# psoc4100sp register map
Vendor: Infineon Technologies; Series: PSOC4100Sp; File version: 1.0
CPU: CM0PLUS r0p1, little endian, MPU, no FPU, VTOR, 2 interrupt priority bits, 28 interrupts
Registers are 32-bit, read-write, reset 0x0 unless marked. A register's access mark holds for its fields unless they carry their own. Offsets are from the block's base; [hi:lo] are bit positions; lines under a group give offsets from that group; {n}, {i} and the like mark numbered series; <NAME> marks a mode.

## CAN — CAN Controller
Base 0x402E0000
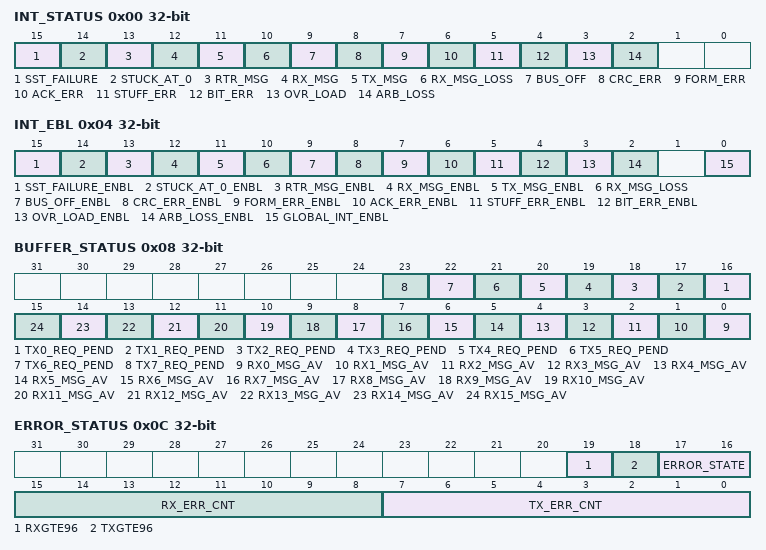
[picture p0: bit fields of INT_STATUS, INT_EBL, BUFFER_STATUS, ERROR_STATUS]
0x00 INT_STATUS — Interrupt Status
  [15] SST_FAILURE write-1-clears — Single shot transmission failure 0: Normal operation 1: A buffer set for single shot transmission experienced an arbitration loss or a bus error during transmission The sst_failure interrupt is set as well when the CAN controller is being stopped while an SST message is in the transmit buffer. user should transmit or remove respective SST messages before stopping the IP, to avoid triggering SST_FAILURE after writing COMMAND.RUN=0.
  [14] STUCK_AT_0 write-1-clears — Stuck at dominant error 0: Normal Operation 1: Indicates if the rx input remains stuack at 0 (dominant level) for more than 16 consecutive bit times. The 'stuck at 0' condition is checked, only when COMMAND.RUN is set
  [13] RTR_MSG write-1-clears — RTR auto-reply message sent 0: Normal operation 1: Indicates that a RTR auto-reply message was sent
  [12] RX_MSG write-1-clears — Indicates that a message was received 0: Normal operation 1: A new message was successfully received and stored in a receive buffer which has its RxIntEBL flag asserted.
  [11] TX_MSG write-1-clears — Indicates that a message was sent 0: Normal operation 1: A message was successfully sent from a transmit buffer which has its TxIntEbl flag asserted.
  [10] RX_MSG_LOSS write-1-clears — when a new message arrives, but the RxMessage flag MSG_AV is set and LINK_FLAG is not set, RX_MSG_LOSS is set, and the new message is discarded.
  [9] BUS_OFF write-1-clears — The CAN has reached the bus off state
  [8] CRC_ERR write-1-clears — A CAN CRC error was detected
  [7] FORM_ERR write-1-clears — A CAN message format error was detected please ignore this interrupt, when ERROR_STATUS.ERROR_STATE=2'B1x
  [6] ACK_ERR write-1-clears — An CAN message acknowledge error was detected
  [5] STUFF_ERR write-1-clears — A bit stuffing error was detected
  [4] BIT_ERR write-1-clears — A bit error was detected
  [3] OVR_LOAD write-1-clears — An overload frame was received, or reactive overload frame condition is detected (ISO-11898-1 section 10.11)
  [2] ARB_LOSS write-1-clears — The arbitration was lost while sending a message
0x04 INT_EBL — Interrupt Enable
  [15] SST_FAILURE_ENBL — See description in INT_STATUS
  [14] STUCK_AT_0_ENBL — See description in INT_STATUS
  [13] RTR_MSG_ENBL — See description in INT_STATUS
  [12] RX_MSG_ENBL — See description in INT_STATUS
  [11] TX_MSG_ENBL — See description in INT_STATUS
  [10] RX_MSG_LOSS — See description in INT_STATUS
  [9] BUS_OFF_ENBL — See description in INT_STATUS
  [8] CRC_ERR_ENBL — See description in INT_STATUS
  [7] FORM_ERR_ENBL — See description in INT_STATUS
  [6] ACK_ERR_ENBL — See description in INT_STATUS
  [5] STUFF_ERR_ENBL — See description in INT_STATUS
  [4] BIT_ERR_ENBL — See description in INT_STATUS
  [3] OVR_LOAD_ENBL — See description in INT_STATUS
  [2] ARB_LOSS_ENBL — See description in INT_STATUS
  [0] GLOBAL_INT_ENBL — global interrupt enable flag '0': All interrupts are disabled '1': Enabled interrupt sources are available
0x08 BUFFER_STATUS ro — RxMessage and TxMessage Buffer Status
  [n+16] TX{n}_REQ_PEND (n=0..7) — TxMessage Buffer Status
  [n] RX{n}_MSG_AV (n=0..15) — RxMessage Buffer Status
0x0C ERROR_STATUS ro — CAN Error Status
  [19] RXGTE96 — The Rx error counter is greater or equal 96
  [18] TXGTE96 — The Tx error counter is greater or equal 96
  [17:16] ERROR_STATE — The error state of the CAN node: '00': error active (normal operation) '01': error passive '1x': bus off
  [15:8] RX_ERR_CNT — The receive error counter according to the CAN 2.0 specification. When in bus-off state, this counter is used to count 128 groups of 11 recessive bits. it is fixed at 255
  [7:0] TX_ERR_CNT — The transmitter error counter according to the CAN standard. When it is greater than 255, it is fixed at 255
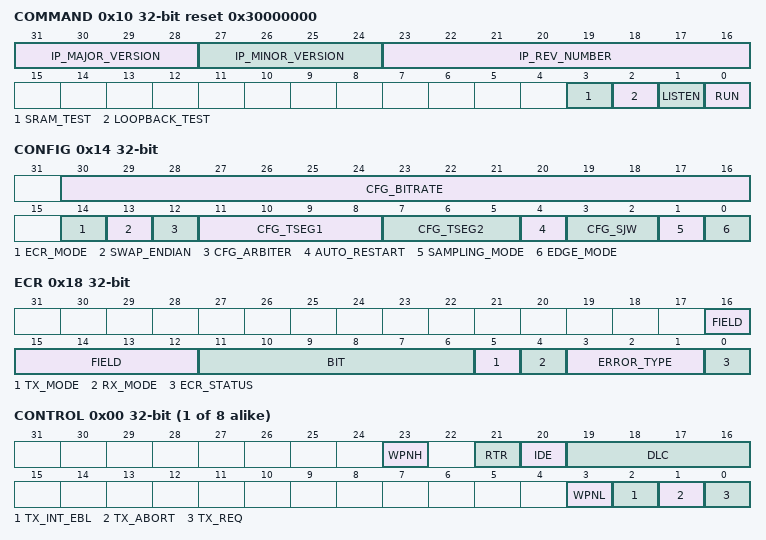
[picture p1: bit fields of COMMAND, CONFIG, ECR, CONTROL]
0x10 COMMAND reset 0x30000000 — CAN Command Register
  [31:28] IP_MAJOR_VERSION ro — IP Major Version Number
  [27:24] IP_MINOR_VERSION ro — IP Minor Version Number
  [23:16] IP_REV_NUMBER ro — IP Revision Number
  [3] SRAM_TEST — SRAM test mode '0': Normal operation '1': Enable SRAM test mode it can be set, only when the IP is stopped (COMMAND.RUN=0, and really finished transition from run mode), this mode will not be used, so it should never be set.
  [2] LOOPBACK_TEST — TEST_MODE[2]. With TEST_MODE[2:1], 00: normal operation 01: Listen-only mode, The output is held at 'R' level. The CANmodule-III is only listening. 10: external loopback mode 11: internal loopback mode
  [1] LISTEN — TEST_MODE[1]
  [0] RUN — Run/Stop mode: '0': Sets the CAN controller into stop mode. Stop mode can be granted only in 'bus idle' field Returns '0' when stopped. '1': Sets the CAN controller into run mode. Returns '1' when running.
0x14 CONFIG — CAN Configuration
  [30:16] CFG_BITRATE — Prescaler for generating the time quantum which defines the TQ: 0: One time quantum equals 1 clock cycle 1: One time quantum equals 2 clock cycles ... 32767: One time quantum equals 32768 clock cycles
  [14] ECR_MODE — Error Capture mode 0: Free running: The ECR register shows the current bit position within the CAN frame 1: Capture mode: The ecr register shows the bit position and type of the last captured CAN error.
  [13] SWAP_ENDIAN — Swap Endian - the byte position of the CAN receive and transmit data fields can be modified to match the endian setting of the processor or the used CAN protocol 0: CAN data byte position is not swapped (big endian) 1: CAN data byte position is swapped (little endian)
  [12] CFG_ARBITER — Transmit buffer arbiter '0': Round robin arbitration '1': Fixed priority arbitration
  [11:8] CFG_TSEG1 — Time segment 1 Length of the first time segment: tseg1 = cfg_tseg1 + 1 Time segment 1 includes the propagation time. cfg_tseg1=0 and cfg_tseg1=1 are not allowed.
  [7:5] CFG_TSEG2 — Time segment 2 Length of the second time segment: tseg2 = cfg_tseg2 + 1 cfg_tseg2=0 is not allowed; cfg_tseg2=1 is only allowed in direct sampling mode.
  [4] AUTO_RESTART — '0': After bus-off, the CAN core must be restarted by setting COMMAND.RUN register. This is the recommended setting. '1': After bus-off, the CAN core is restarting automatically after 128 groups of 11 recessive bits
  [3:2] CFG_SJW — Synchronization jump width - 1 sjw <= tseg1 and sjw <= tseg2
  [1] SAMPLING_MODE — CAN bus bit sampling '0': One sampling point is used in the receiver path '1': 3 sampling points with majority decision are used
  [0] EDGE_MODE — CAN bus synchronization logic '0': Edge from 'R' to 'D' is used for synchronization '1': Both edges are used Note, only 'R' to 'D' edge shall be used for synchronization per ISO-11898-1 spec, so this bit should always be set 0 (by default)
0x18 ECR — Error Capture Register
  [16:12] FIELD ro — Field - 0x00 : Stopped 0x01 : Synchronize 0x05 : Interframe 0x06 : Bus Idle 0x07 : Start of Frame 0x08 : Arbitration 0x09 : Control 0x0A : Data 0x0B : CRC 0x0C : ACK 0x0D : End of frame 0x10 : Error flag 0x11 : Error echo 0x12 : Error delimiter 0x18 : Overload flag 0x19 : Overload echo 0x1A : Overload delimiter Others : N/A
  [11:6] BIT ro — Bit number inside of Field
  [5] TX_MODE ro — TX Mode - 0: No status 1: CAN Controller is transmitter
  [4] RX_MODE ro — RX Mode - 0: No status 1: CAN Controller is receiver
  [3:1] ERROR_TYPE ro — Error type - 000 : Arbitration loss 001 : Bit Error 010 : Bit Stuffing Error 011 : Acknowledge Error 100 : Form Error 101 : CRC Error Others : N/A
  [0] ECR_STATUS — ECR STATUS - 0: ECR register captured an error, or it is in free running mode 1: ECR register is armed
{0x20+0x10*i} TX[{i}] (i=0..7) group — TxMessage Buffer control/command
  0x00 CONTROL (reset mask 0xF) — TxMessage Buffer control/command
    [23] WPNH
    [21] RTR — Remote Bit '0': This is a standard message '1': This is an RTR message
    [20] IDE — Extended Identifier Bit '0': This is a standard format message '1': This is an extended format message
    [19:16] DLC — DLC, Data Length Code Invalid values are transmitted as they are, but the number of data bytes is limited to eight. 0: Message has 0 data byte, data[63:0] is not used 1: Message has 1 data byte, data[63:56] is used ... 8: Message has 8 data bytes, data[63:0] is used 9-15: Message has 8 data bytes
    [3] WPNL
    [2] TX_INT_EBL — Tx Interrupt Enable '0': Interrupt disabled '1': Interrupt enabled, successful message transmission sets the TxMsg
    [1] TX_ABORT — Transmit Abort Request '0': idle '1': Requests removal of a pending message. The message is removed the next time an arbitration loss happens or a CAN error is detected. The flag is cleared when the message was removed or when the message won arbitration. The TxReq flag is released at the same time when there is a pending TX message (read out TxReq=1 and TxAbort=0), Writing TxReq=1 and TxAbort=1 has no effect. for SST message,when the message is aborted, the TxReq fag is cleared, but the TxAbort fag remains asserted.
    [0] TX_REQ — TxReq, Transmit Request Write: '0': idle '1': Message Transmit Request5 Read: '0': TxReq completed '1': TxReq pending
  0x04 ID reset not defined — TxMessage Buffer Identifier
    [31:3] ID — Message identifier
  0x08 DATA_HIGH reset not defined — TxMessage Buffer Data high
    [31:0] DATA — Data[63:32] when CONFIG.SWAP_ENDIAN=0(Big Endian, by default), the sequence of DATA transmission is, {DATA_HIGH[31:0], DATA_LOW[31:0]} if only byte is defined in CONTROL.DLC, DATA_HIGH[7:0] will be transmitted when CONFIG.SWAP_ENDIAN=1(Little Endian), the sequence of DATA transmission is, {DATA_HIGH[7:0], [15:8], [23:16], [31:24], DATA_LOW[7:0], [15:8], [23:16], [31:24]} if only byte is defined in CONTROL.DLC, DATA_HIGH[7:0] will be transmitted
  0x0C DATA_LOW reset not defined — TxMessageBuffer Data low
    [31:0] DATA — Data[31:0]
{0xA0+0x20*i} RX[{i}] (i=0..15) group — RxMessage buffer control/command
  0x00 CONTROL (reset mask 0xFF) — RxMessage Buffer control/command
    [23] WPNH
    [21] RTR_MSG — Remote Bit '1': This is an RTR message '0': This is a regular message depending on RTR_REPLY setting, 0, this field will be updated by received data/remote frame 1, this field should be set to 0 (data frame type) by user in advance, will not be updated by received data/remote frame, and will be sent out in responsive data frame
    [20] IDE_FMT — Extended Identifier Bit '1': This is an extended format message '0': This is a standard format message depending on RTR_REPLY setting, 0, this field will be updated by received data/remote frame 1, this field should be aligned offline and set by user in advance, will not be updated by received data/remote frame, and will be sent out in responsive data frame
    [19:16] DLC — DLC, Data Length Code 0: Message has 0 data bytes, data[63:0] is notvalid 1: Message has 1 data byte, data[63:56] is valid .. 8: Message has 8 data bytes, data[63:0] is valid 9-15: Message has 8 data bytes depending on RTR_REPLY setting, 0, this field will be updated by received data/remote frame 1, this field should be aligned offline and set by user in advance, will not be updated by received data/remote frame, and will be sent out in responsive data frame
    [7] WPNL
    [6] LINK_FLAG — Link Flag '0': This buffer is not linked to the next '1': This buffer is linked with next buffer
    [5] RX_INT_EBL — RxIntEbl, Receive Interrupt Enable '0': Interrupt generation is disabled '1': Interrupt generation is enabled
    [4] RTR_REPLY — automatic message reply upon receipt of an RTR message '0': Automatic RTR message handling disabled '1': Automatic RTR message handling enabled when this bit is set, only RTR message can be received, by setting AMR.RTR=0, AMR.RTR=1. Otherwise, the RTR reply message content will corrupted by received non-RTR message.
    [3] BUFFER_EN — Buffer Enable '0': Buffer is disabled '1': Buffer is enabled
    [2] RTR_ABORT — RTR Abort Request '0': Idle '1': Requests removal of a pending RTR message reply. The flag is cleared when the message was removed or when the message won arbitration. The TxReq flag is released at the same time.
    [1] RTR_REPLY_PEND ro — RTReply_pending status '0': No RTR reply request pending '1': RTR reply request pending
    [0] MSG_AV_RTRSENT write-1-clears — Msg Available/RTR Sent If RTReply flag is set, this bit shows if an RTR auto-reply message has been sent, otherwise it indicates if the buffer contains a valid message. Read: '0': Idle '1': New message available (RTRreply=0), RTR auto-reply message sent (RTRreply=1). Write: '0': Idle '1': Acknowledges receipt of new message or transmission of RTR auto-reply message.
  0x04 ID reset not defined — Identifier
    [31:3] ID — RxMessage: Identifier
  0x08 DATA_HIGH reset not defined — RxMessage Data high
    [31:0] DATA — Data[63:32]
  0x0C DATA_LOW reset not defined — RxMessage Data low
    [31:0] DATA — Data[31:0]
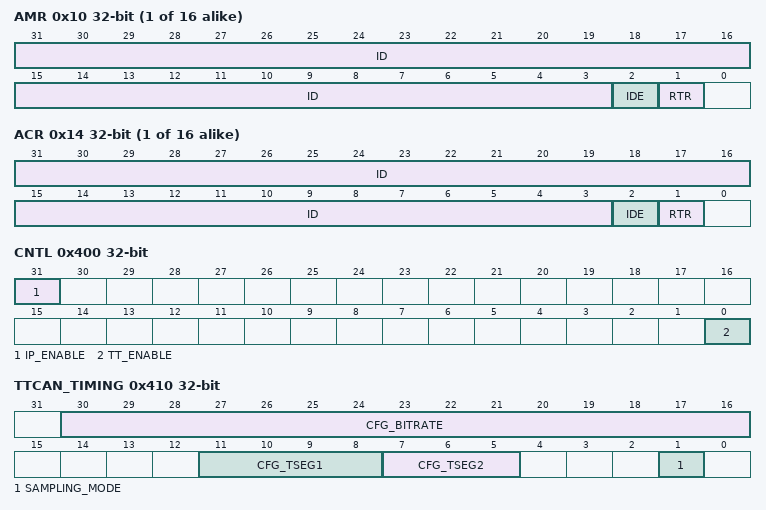
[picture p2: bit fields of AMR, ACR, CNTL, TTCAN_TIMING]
  0x10 AMR reset not defined — Acceptance Mask Register
    [31:3] ID — Identifier it cannot be used to match both 11bit and 29bit identifiers, in case of 11bit identifiers, lower 18bits should be all ones (don't care)
    [2] IDE
    [1] RTR
  0x14 ACR reset not defined — Acceptance Code Register
    [31:3] ID — Identifier
    [2] IDE
    [1] RTR
  0x18 AMR_DATA reset not defined — Acceptance Mask Register - Data
    [15:0] DATAL — Data[63:48], when DUT is NOT configured to receive only DATA frame, this register should be configured with all ones (don't care)
  0x1C ACR_DATA reset not defined — Acceptance Code Register - Data
    [15:0] DATAL — Data[63:48]
0x400 CNTL — Control
  [31] IP_ENABLE — IP Enable/Disable 0=IP is disabled/reset 1=IP is enabled/running
  [0] TT_ENABLE — TTCAN enable/disable 0=TTCAN is disabled; Interrupt_can is sourced from 3PIP. INT_EBL.GLOBAL_INT_ENBL & (INT_EBL[i] & INT_STATUS[i]) 1=TTCAN is enabled; Interrupt_can is sourced from INTR_CAN_MASKED.
0x404 TTCAN_COUNTER — TTCAN Level1 16-Bit local time counter
  [31:16] LOCAL_TIME — Bit time counter in TTCAN level 1
0x408 TTCAN_COMPARE reset 0xFFFF0000 — TTCAN Level1 compare configuration
  [31:16] TIME_MARK — compare target, when TTCAN_COUNTER.LOCAL_TIME counts to TT_COMPARE, INTR_CAN.TT_COMPARE will be set
0x40C TTCAN_CAPTURE ro — TTCAN Level1 capture configuration
  [31:16] SYNC_MARK — copy TTCAN_COUNTER.LOCAL_TIME to TTCAN_CAPTURE.SYNC_MARK, when SOF detected. when new event triggers, new LOCAL_TIME value will overwrite previous SYNC_MARK value
0x410 TTCAN_TIMING — TTCAN Level1 timing configuration, duplicate of CONFIG fields
  [30:16] CFG_BITRATE — Prescaler for generating the time quantum which defines the TQ: 0: One time quantum equals 1 clock cycle 1: One time quantum equals 2 clock cycles ... 32767: One time quantum equals 32768 clock cycles
  [11:8] CFG_TSEG1 — Time segment 1 Length of the first time segment: tseg1 = cfg_tseg1 + 1 Time segment 1 includes the propagation time. cfg_tseg1=0 and cfg_tseg1=1 are not allowed.
  [7:5] CFG_TSEG2 — Time segment 2 Length of the second time segment: tseg2 = cfg_tseg2 + 1 cfg_tseg2=0 is not allowed; cfg_tseg2=1 is only allowed in direct sampling mode.
  [1] SAMPLING_MODE — CAN bus bit sampling '0': One sampling point is used in the receiver path '1': 3 sampling points with majority decision are used
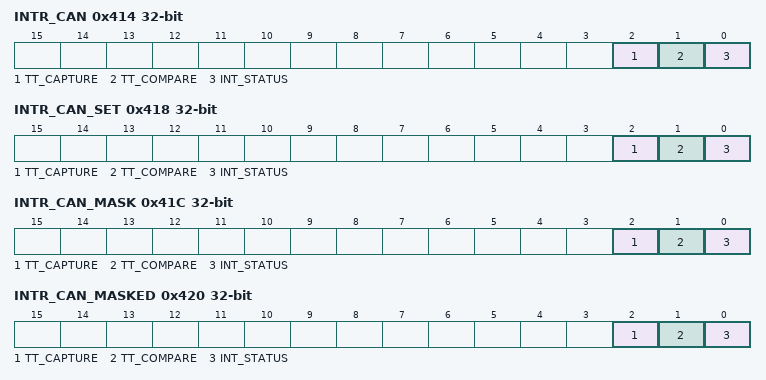
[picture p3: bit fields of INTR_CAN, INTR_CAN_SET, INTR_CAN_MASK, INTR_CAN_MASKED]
0x414 INTR_CAN — CAN Interrupt Cause (TTCAN + INT_STATUS Or)
  [2] TT_CAPTURE write-1-clears — Triggers when LOCAL_TIME is saved to TT_CAPTURE, on SOF detection
  [1] TT_COMPARE write-1-clears — Triggers when LOCAL_TIME is equal to TT_COMPARE
  [0] INT_STATUS write-1-clears — Triggers when any enabled (INT_EBL) interrupt are set in INT_STATUS
0x418 INTR_CAN_SET — CAN Interrupt Set (TTCAN + INT_STATUS Or)
  [2] TT_CAPTURE write-1-sets — Write with '1' to set corresponding bit in interrupt request register.
  [1] TT_COMPARE write-1-sets — Write with '1' to set corresponding bit in interrupt request register.
  [0] INT_STATUS write-1-sets — Write with '1' to set corresponding bit in interrupt request register.
0x41C INTR_CAN_MASK — CAN Interrupt Mask (TTCAN + INT_STATUS Or)
  [2] TT_CAPTURE — Mask bit for corresponding bit in interrupt request register.
  [1] TT_COMPARE — Mask bit for corresponding bit in interrupt request register.
  [0] INT_STATUS — Mask bit for corresponding bit in interrupt request register.
0x420 INTR_CAN_MASKED ro — Can Interrupt Masked (TTCAN + INT_STATUS Or)
  [2] TT_CAPTURE — Logical and of corresponding request and mask bits.
  [1] TT_COMPARE — Logical and of corresponding request and mask bits.
  [0] INT_STATUS — Logical and of corresponding request and mask bits.

## Notices in the file
(c) 2016-2026, Infineon Technologies AG or an affiliate of
Infineon Technologies AG.
SPDX-License-Identifier: Apache-2.0
Licensed under the Apache License, Version 2.0 (the "License");
you may not use this file except in compliance with the License.
You may obtain a copy of the License at
http://www.apache.org/licenses/LICENSE-2.0
Unless required by applicable law or agreed to in writing, software
distributed under the License is distributed on an "AS IS" BASIS,
WITHOUT WARRANTIES OR CONDITIONS OF ANY KIND, either express or implied.
See the License for the specific language governing permissions and
limitations under the License.
